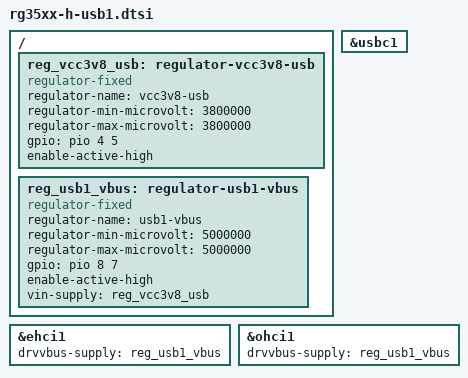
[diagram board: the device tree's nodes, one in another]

/* second USB port: PI7 VBUS switch on a 3.8 V rail from PE5 (rocknix) */
/ {
	reg_vcc3v8_usb: regulator-vcc3v8-usb {
		compatible = "regulator-fixed";
		regulator-name = "vcc3v8-usb";
		regulator-min-microvolt = <3800000>;
		regulator-max-microvolt = <3800000>;
		gpio = <&pio 4 5 GPIO_ACTIVE_HIGH>; /* PE5 */
		enable-active-high;
	};

	reg_usb1_vbus: regulator-usb1-vbus {
		compatible = "regulator-fixed";
		regulator-name = "usb1-vbus";
		regulator-min-microvolt = <5000000>;
		regulator-max-microvolt = <5000000>;
		gpio = <&pio 8 7 GPIO_ACTIVE_HIGH>; /* PI7 */
		enable-active-high;
		vin-supply = <&reg_vcc3v8_usb>;
	};
};

/* sunxi-hci only enables a port whose usbc node has a status */
&usbc1 {
	status = "okay";
};

&ehci1 {
	drvvbus-supply = <&reg_usb1_vbus>;
	status = "okay";
};

&ohci1 {
	drvvbus-supply = <&reg_usb1_vbus>;
	status = "okay";
};
